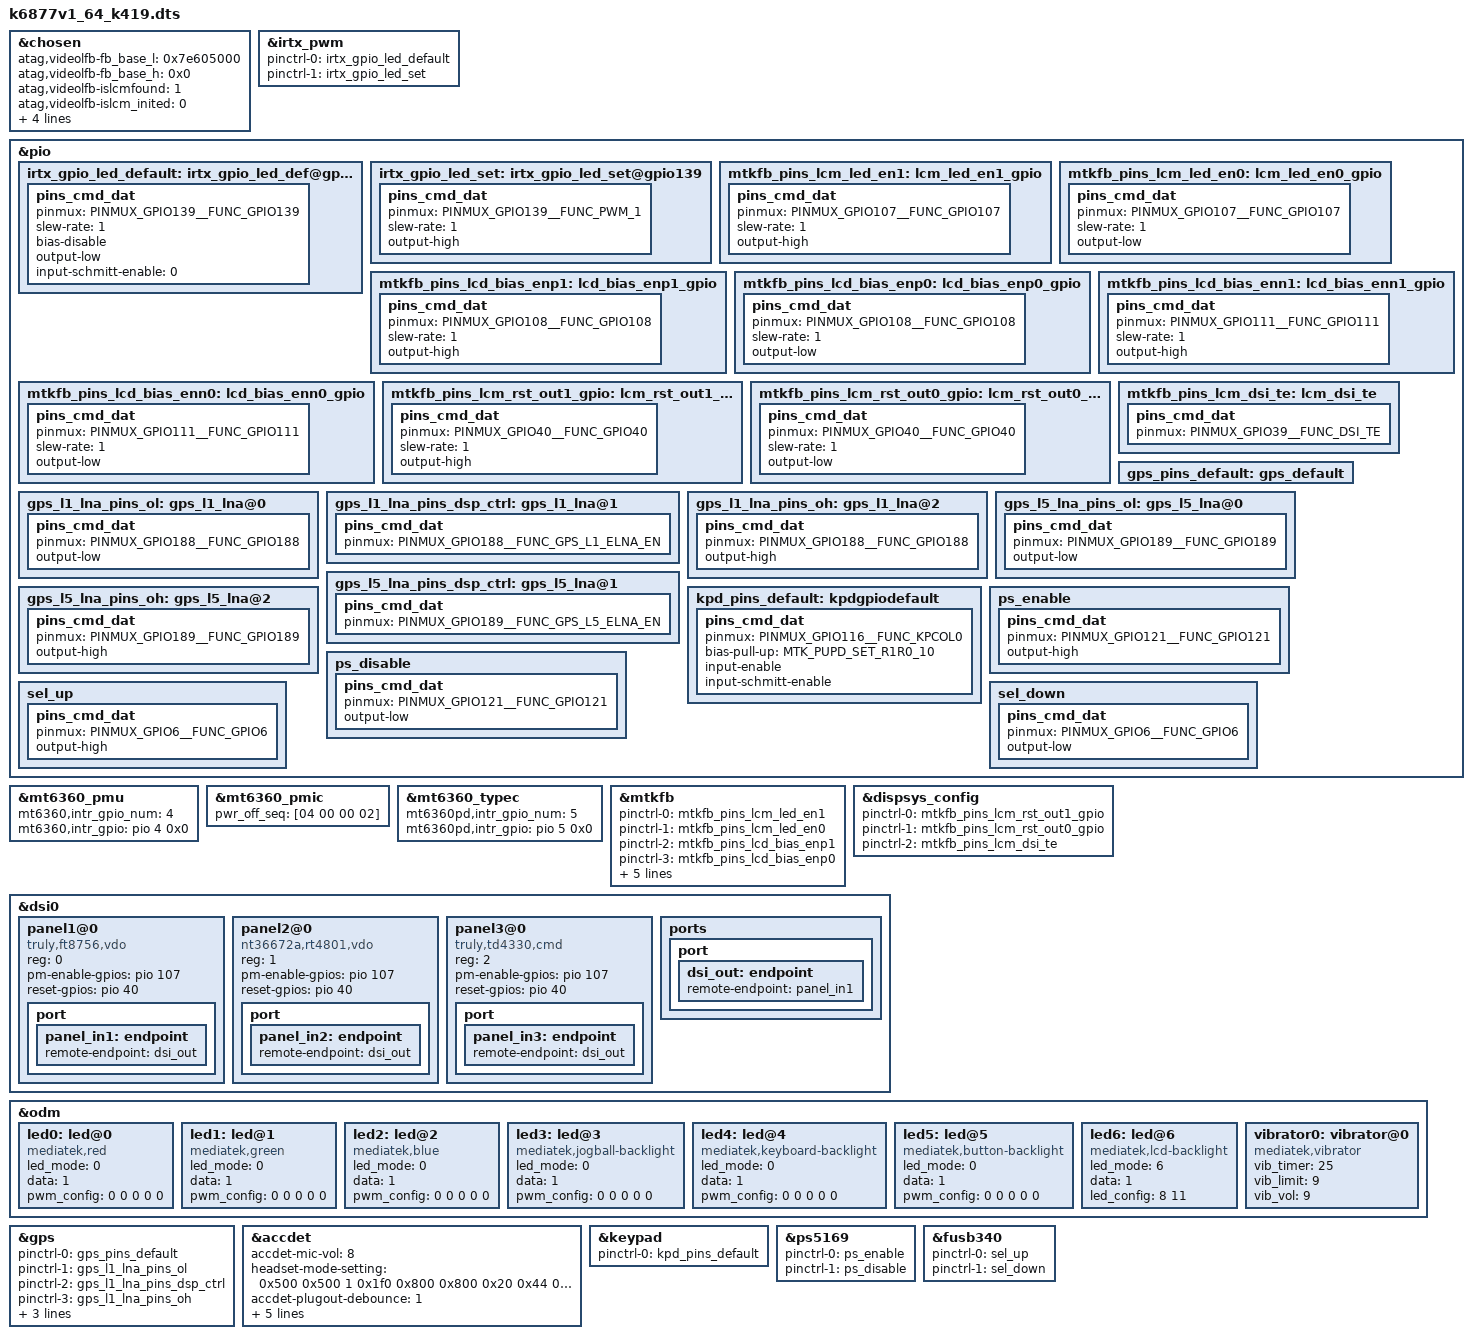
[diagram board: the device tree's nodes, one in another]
// SPDX-License-Identifier: GPL-2.0
/*
 * Copyright (c) 2021 MediaTek Inc.
 */

/dts-v1/;
/plugin/;
#include <dt-bindings/interrupt-controller/irq.h>
#include <dt-bindings/interrupt-controller/arm-gic.h>
#include <dt-bindings/pinctrl/mt6877-pinfunc.h>

/* chosen */
&chosen {
	atag,videolfb-fb_base_l = <0x7e605000>;
	atag,videolfb-fb_base_h = <0x0>;
	atag,videolfb-islcmfound = <1>;
	atag,videolfb-islcm_inited = <0>;
	atag,videolfb-fps= <6000>;
	atag,videolfb-vramSize= <0x1be0000>;
	atag,videolfb-lcmname=
		"td4330_fhdp_dsi_cmd_auo_rt4831_drv";
};

/* IRTX GPIO Start */
&irtx_pwm {
	pinctrl-names = "irtx_gpio_led_default", "irtx_gpio_led_set";
	pinctrl-0 = <&irtx_gpio_led_default>;
	pinctrl-1 = <&irtx_gpio_led_set>;
	status = "okay";
};
&pio {
	/* IRTX GPIO Settings -Start */
	/* default: GPIO0, output, high */
	irtx_gpio_led_default:irtx_gpio_led_def@gpio139 {
		pins_cmd_dat {
			pinmux = <PINMUX_GPIO139__FUNC_GPIO139>;
			slew-rate = <1>;
			bias-disable;
			output-low;
			input-schmitt-enable = <0>;
		};
	};

	irtx_gpio_led_set:irtx_gpio_led_set@gpio139 {
		pins_cmd_dat {
			pinmux = <PINMUX_GPIO139__FUNC_PWM_1>;
			slew-rate = <1>;
			output-high;
		};
	};
}; /* IRTX GPIO Settings -End */

&mt6360_pmu {
	mt6360,intr_gpio_num = <4>; /* direct defined GPIO num */
	mt6360,intr_gpio = <&pio 4 0x0>;
};

&mt6360_pmic {
	pwr_off_seq = [04 00 00 02];
};

&mt6360_typec {
	mt6360pd,intr_gpio_num = <5>; /* direct defined GPIO num */
	mt6360pd,intr_gpio = <&pio 5 0x0>;
};

&pio {
	mtkfb_pins_lcm_led_en1: lcm_led_en1_gpio {
		pins_cmd_dat {
			pinmux = <PINMUX_GPIO107__FUNC_GPIO107>;
			slew-rate = <1>;
			output-high;
		};
	};

	mtkfb_pins_lcm_led_en0: lcm_led_en0_gpio {
		pins_cmd_dat {
			pinmux = <PINMUX_GPIO107__FUNC_GPIO107>;
			slew-rate = <1>;
			output-low;
		};
	};

	mtkfb_pins_lcd_bias_enp1: lcd_bias_enp1_gpio {
		pins_cmd_dat {
			pinmux = <PINMUX_GPIO108__FUNC_GPIO108>;
			slew-rate = <1>;
			output-high;
		};
	};

	mtkfb_pins_lcd_bias_enp0: lcd_bias_enp0_gpio {
		pins_cmd_dat {
			pinmux = <PINMUX_GPIO108__FUNC_GPIO108>;
			slew-rate = <1>;
			output-low;
		};
	};

	mtkfb_pins_lcd_bias_enn1: lcd_bias_enn1_gpio {
		pins_cmd_dat {
			pinmux = <PINMUX_GPIO111__FUNC_GPIO111>;
			slew-rate = <1>;
			output-high;
		};
	};

	mtkfb_pins_lcd_bias_enn0: lcd_bias_enn0_gpio {
		pins_cmd_dat {
			pinmux = <PINMUX_GPIO111__FUNC_GPIO111>;
			slew-rate = <1>;
			output-low;
		};
	};

	mtkfb_pins_lcm_rst_out1_gpio: lcm_rst_out1_gpio {
		pins_cmd_dat {
			pinmux = <PINMUX_GPIO40__FUNC_GPIO40>;
			slew-rate = <1>;
			output-high;
		};
	};

	mtkfb_pins_lcm_rst_out0_gpio: lcm_rst_out0_gpio {
		pins_cmd_dat {
			pinmux = <PINMUX_GPIO40__FUNC_GPIO40>;
			slew-rate = <1>;
			output-low;
		};
	};
	mtkfb_pins_lcm_dsi_te: lcm_dsi_te {
		pins_cmd_dat {
			pinmux = <PINMUX_GPIO39__FUNC_DSI_TE>;
		};
	};
};

&mtkfb {
	pinctrl-names = "lcm_led_en1_gpio", "lcm_led_en0_gpio",
		"lcd_bias_enp1_gpio", "lcd_bias_enp0_gpio",
		"lcd_bias_enn1_gpio", "lcd_bias_enn0_gpio",
		"lcm_rst_out1_gpio", "lcm_rst_out0_gpio",
		"mode_te_te";
	pinctrl-0 = <&mtkfb_pins_lcm_led_en1>;
	pinctrl-1 = <&mtkfb_pins_lcm_led_en0>;
	pinctrl-2 = <&mtkfb_pins_lcd_bias_enp1>;
	pinctrl-3 = <&mtkfb_pins_lcd_bias_enp0>;
	pinctrl-4 = <&mtkfb_pins_lcd_bias_enn1>;
	pinctrl-5 = <&mtkfb_pins_lcd_bias_enn0>;
	pinctrl-6 = <&mtkfb_pins_lcm_rst_out1_gpio>;
	pinctrl-7 = <&mtkfb_pins_lcm_rst_out0_gpio>;
	pinctrl-8 = <&mtkfb_pins_lcm_dsi_te>;
	status = "okay";
};
&dispsys_config {
	pinctrl-names =
		"lcm_rst_out1_gpio", "lcm_rst_out0_gpio",
		"mode_te_te";
	pinctrl-0 = <&mtkfb_pins_lcm_rst_out1_gpio>;
	pinctrl-1 = <&mtkfb_pins_lcm_rst_out0_gpio>;
	pinctrl-2 = <&mtkfb_pins_lcm_dsi_te>;
	status = "okay";
};

&dsi0 {
	status = "okay";
	#address-cells = <1>;
	#size-cells = <0>;
	panel1@0 {
		compatible = "truly,ft8756,vdo";
		reg = <0>;
		pm-enable-gpios = <&pio 107 0>;
		reset-gpios = <&pio 40 0>;
		pinctrl-names = "default";
		port {
			panel_in1: endpoint {
				remote-endpoint = <&dsi_out>;
			};
		};
	};
	panel2@0 {
		compatible = "nt36672a,rt4801,vdo";
		reg = <1>;
		pm-enable-gpios = <&pio 107 0>;
		reset-gpios = <&pio 40 0>;
		pinctrl-names = "default";
		port {
			panel_in2: endpoint {
				remote-endpoint = <&dsi_out>;
			};
		};
	};
	panel3@0 {
		compatible = "truly,td4330,cmd";
		reg = <2>;
		pm-enable-gpios = <&pio 107 0>;
		reset-gpios = <&pio 40 0>;
		pinctrl-names = "default";
		port {
			panel_in3: endpoint {
				remote-endpoint = <&dsi_out>;
			};
		};
	};
	ports {
		port {
			dsi_out: endpoint {
				remote-endpoint = <&panel_in1>;
			};
		};
	};
};

&odm {
	led0:led@0 {
		compatible = "mediatek,red";
		led_mode = <0>;
		data = <1>;
		pwm_config = <0 0 0 0 0>;
	};
	led1:led@1 {
		compatible = "mediatek,green";
		led_mode = <0>;
		data = <1>;
		pwm_config = <0 0 0 0 0>;
	};
	led2:led@2 {
		compatible = "mediatek,blue";
		led_mode = <0>;
		data = <1>;
		pwm_config = <0 0 0 0 0>;
	};
	led3:led@3 {
		compatible = "mediatek,jogball-backlight";
		led_mode = <0>;
		data = <1>;
		pwm_config = <0 0 0 0 0>;
	};
	led4:led@4 {
		compatible = "mediatek,keyboard-backlight";
		led_mode = <0>;
		data = <1>;
		pwm_config = <0 0 0 0 0>;
	};
	led5:led@5 {
		compatible = "mediatek,button-backlight";
		led_mode = <0>;
		data = <1>;
		pwm_config = <0 0 0 0 0>;
	};
	led6:led@6 {
		compatible = "mediatek,lcd-backlight";
		led_mode = <6>;
		data = <1>;
		led_config = <8 11>;
	};
	vibrator0:vibrator@0 {
		compatible = "mediatek,vibrator";
		vib_timer = <25>;
		vib_limit = <9>;
		vib_vol= <9>;
	};
};

/* GPS GPIO standardization start */
&pio {
	gps_pins_default: gps_default {
	};
	gps_l1_lna_pins_ol: gps_l1_lna@0 {
		pins_cmd_dat {
			pinmux = <PINMUX_GPIO188__FUNC_GPIO188>;
			output-low;
		};
	};
	gps_l1_lna_pins_dsp_ctrl: gps_l1_lna@1 {
		pins_cmd_dat {
			pinmux = <PINMUX_GPIO188__FUNC_GPS_L1_ELNA_EN>;
		};
	};
	gps_l1_lna_pins_oh: gps_l1_lna@2 {
		pins_cmd_dat {
			pinmux = <PINMUX_GPIO188__FUNC_GPIO188>;
			output-high;
		};
	};
	gps_l5_lna_pins_ol: gps_l5_lna@0 {
		pins_cmd_dat {
			pinmux = <PINMUX_GPIO189__FUNC_GPIO189>;
			output-low;
		};
	};
	gps_l5_lna_pins_dsp_ctrl: gps_l5_lna@1 {
		pins_cmd_dat {
			pinmux = <PINMUX_GPIO189__FUNC_GPS_L5_ELNA_EN>;
		};
	};
	gps_l5_lna_pins_oh: gps_l5_lna@2 {
		pins_cmd_dat {
			pinmux = <PINMUX_GPIO189__FUNC_GPIO189>;
			output-high;
		};
	};
};
&gps {
	pinctrl-names = "default",
		"gps_l1_lna_disable",
		"gps_l1_lna_dsp_ctrl",
		"gps_l1_lna_enable",
		"gps_l5_lna_disable",
		"gps_l5_lna_dsp_ctrl",
		"gps_l5_lna_enable";
	pinctrl-0 = <&gps_pins_default>;
	pinctrl-1 = <&gps_l1_lna_pins_ol>;
	pinctrl-2 = <&gps_l1_lna_pins_dsp_ctrl>;
	pinctrl-3 = <&gps_l1_lna_pins_oh>;
	pinctrl-4 = <&gps_l5_lna_pins_ol>;
	pinctrl-5 = <&gps_l5_lna_pins_dsp_ctrl>;
	pinctrl-6 = <&gps_l5_lna_pins_oh>;
	status = "okay";
};
/* GPS GPIO standardization end */

&accdet {
	/* accdet micbias voltage: 0x09:2.85v 0x08:2.8v 0x07,
	 * 2.7v;0x05,2.5v;0x02,1.9v
	 */
	accdet-mic-vol = <8>;
	/* accdet pwm_width, pwm_thresh, fall_delay, rise_delay
	 * debounce0, debounce1, debounce3, debounce4
	 * eint pwm_width, eint pwm_thresh
	 * eint deb(debounce0, debounce1, debounce2, debounce3), inv_debounce
	 */
	headset-mode-setting = <0x500 0x500 1 0x1f0
				0x800 0x800 0x20 0x44
				0x4 0x1
				0x5 0x3 0x3 0x5 0xe>;
	accdet-plugout-debounce = <1>;
	/*1:ACC mode, 2:low cost without in bias, 6:low cost with in bias*/
	accdet-mic-mode = <2>;
	/*0--MD_MAX--UP_MAX--DW_MAX*/
	headset-three-key-threshold = <0 80 220 400>;
	headset-three-key-threshold-CDD = <0 121 192 600>;
	/*0--MD_MAX--VOICE_MAX--UP_MAX--DW_MAX*/
	headset-four-key-threshold = <0 58 121 192 400>;

	/* select VTH to 2v and 500k, use internal resitance */
	eint_use_ext_res = <0>;
	status = "okay";
};

/* keypad start */
&keypad {
	pinctrl-names = "default";
	pinctrl-0 = <&kpd_pins_default>;
};

&pio {
	kpd_pins_default: kpdgpiodefault {
		pins_cmd_dat {
			pinmux = <PINMUX_GPIO116__FUNC_KPCOL0>;
			bias-pull-up = <MTK_PUPD_SET_R1R0_10>;
			input-enable;
			input-schmitt-enable;
		};
	};
};
/* keypad end */

&ps5169{
	pinctrl-names = "enable", "disable";
	pinctrl-0 = <&ps_enable>;
	pinctrl-1 = <&ps_disable>;
	status = "okay";
};

&fusb340 {
	pinctrl-names = "sel_up", "sel_down";
	pinctrl-0 = <&sel_up>;
	pinctrl-1 = <&sel_down>;
	status = "okay";
};

&pio {
	ps_enable: ps_enable {
		pins_cmd_dat {
			pinmux = <PINMUX_GPIO121__FUNC_GPIO121>;
			output-high;
		};
	};

	ps_disable: ps_disable {
		pins_cmd_dat {
			pinmux = <PINMUX_GPIO121__FUNC_GPIO121>;
			output-low;
		};
	};

	sel_up: sel_up {
		pins_cmd_dat {
			pinmux = <PINMUX_GPIO6__FUNC_GPIO6>;
			output-high;
		};
	};

	sel_down: sel_down {
		pins_cmd_dat {
			pinmux = <PINMUX_GPIO6__FUNC_GPIO6>;
			output-low;
		};
	};
};

#include "k6877v1_64_k419/cust.dtsi"
#include "mediatek/cust_mt6877_touch_1080x2300.dtsi"
#include "mediatek/cust_mt6877_camera.dtsi"
/*End of this file, DO NOT ADD ANYTHING HERE*/

